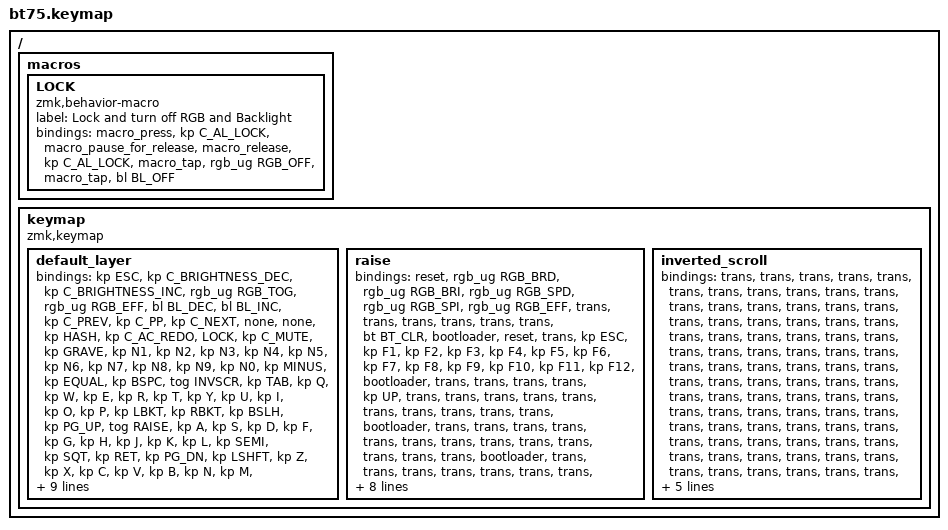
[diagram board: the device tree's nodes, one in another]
#include <behaviors.dtsi>
#include <dt-bindings/zmk/keys.h>
#define HOST_OS 2
#include "../zmk-nodefree-config/helper.h"
#include <dt-bindings/zmk/bt.h>
#include <dt-bindings/zmk/rgb.h>
#include <dt-bindings/zmk/backlight.h>
#include <dt-bindings/zmk/ext_power.h>


/ {
    macros {
        LOCK: LOCK {
            label = "Lock and turn off RGB and Backlight";
            compatible = "zmk,behavior-macro";
            #binding-cells = <0>;
            bindings
			    = <&macro_press &kp C_AL_LOCK>
			    , <&macro_pause_for_release>
			    , <&macro_release &kp C_AL_LOCK>
			    , <&macro_tap &rgb_ug RGB_OFF>
			    , <&macro_tap &bl BL_OFF>
			    ;
        };
    };
};

#define DEFAULT 0
#define RAISE   1
#define INVSCR  2


/ {
	keymap {
		compatible = "zmk,keymap";
		default_layer {
				// ------------------------------------------------------------------------------------------------------------
				// | ESC | F1  | F2  | F3  | F4  | F5  | F6  | F7  | F9  | F9  | F10 | F11 | F12 | PSCRN | INS | DEL	|
				// |  `  |  1  |  2  |  3  |  4  |  5  |  6  |  7  |  8  |  9  |  0  |  -  |  =  |   BKSP   | HOME	|
				// | TAB  |  Q  |  W  |  E  |  R  |  T  |  Y  |  U  |  I  |  O  |  P  |  [  |  ]  |    \    | PG UP |
				// | CAPS  |  A  |  S  |  D  |  F  |  G  |  H  |  J  |  K  |  L  |  ;  |  '  |     ENTER     | PG DN |
				// |  SHIFT    |  Z  |  X  |  C  |  V  |  B  |  N  |  M  |  ,  |  .  | /   |    SHIFT |  UP  |  END  |
				// |  CTL  |  WIN  |  ALT  |            SPACE               | ALT | 1  | CTRL |  LEFT | DOWN | RIGHT |
				// ------------------------------------------------------------------------------------------------------------
			bindings = <
			// 	1 			2 						3 						4 					5 					6 			7 			8 			9 			10 			11 		 		12 	  				13 	   					14 				15 		 			16
				&kp ESC		&kp C_BRIGHTNESS_DEC 	&kp C_BRIGHTNESS_INC 	&rgb_ug RGB_TOG 	&rgb_ug RGB_EFF 	&bl BL_DEC 	&bl BL_INC 	&kp C_PREV 	&kp C_PP 	&kp C_NEXT 	&none 			&none 				&kp HASH 				&kp C_AC_REDO	&LOCK 				&kp C_MUTE
				&kp GRAVE 	&kp N1 					&kp N2 					&kp N3 				&kp N4 				&kp N5 		&kp N6 		&kp N7 		&kp N8 		&kp N9 		&kp N0 			&kp MINUS 			&kp EQUAL 				&kp BSPC 							&tog INVSCR
				&kp TAB		&kp Q 					&kp W 					&kp E 				&kp R 				&kp T 		&kp Y 		&kp U 		&kp I 		&kp O 		&kp P 			&kp LBKT 			&kp RBKT 				&kp BSLH							&kp PG_UP
				&tog RAISE 	&kp A 					&kp S 					&kp D 				&kp F 				&kp G 		&kp H 		&kp J 		&kp K 		&kp L 		&kp SEMI 		&kp SQT 						 			&kp RET								&kp PG_DN
				&kp LSHFT 				 			&kp Z 					&kp X 				&kp C 				&kp V 		&kp B 		&kp N 		&kp M 		&kp COMMA 	&kp DOT 		&kp SLASH			&kp LC(LS(LG(LALT))) 					&kp UP 				&kp C_MENU
				&kp LCTRL 	&kp LALT 				&kp LGUI 														&kp SPACE 													&kp RGUI 		&mo RAISE 			&kp LC(LS(LALT))		&kp LEFT 		&kp DOWN 			&kp RIGHT
			>;
			sensor-bindings = < &inc_dec_kp C_AC_SCROLL_UP C_AC_SCROLL_DOWN &inc_dec_kp C_VOL_UP C_VOL_DN &inc_dec_kp C_VOL_UP C_VOL_DN>;
		};
		raise {
			bindings = <
			// 	1 			2 						3 						4 					5 					6 					7 			8 		9 		10 			11 		 	12 	  			13 	   		14 				15 		 	16
				&reset		&rgb_ug RGB_BRD 		&rgb_ug RGB_BRI 		&rgb_ug RGB_SPD 	&rgb_ug RGB_SPI 	&rgb_ug RGB_EFF 	&trans 		&trans	&trans	&trans		&trans		&trans			&bt BT_CLR	&bootloader		&reset		&trans
				&kp ESC		&kp F1 					&kp F2 					&kp F3 				&kp F4 				&kp F5 				&kp F6 		&kp F7	&kp F8	&kp F9		&kp F10		&kp F11			&kp F12		&bootloader 	&trans		&trans
				&trans		&trans 					&kp UP 					&trans 				&trans 				&trans 				&trans 		&trans	&trans	&trans		&trans		&trans			&trans		&bootloader		&trans
				&trans		&trans 					&trans 					&trans 				&trans 				&trans 				&trans 		&trans	&trans	&trans		&trans		&trans						&bootloader					&trans
				&trans		&trans					&trans 					&trans 				&trans 				&trans 				&trans 		&trans	&trans	&trans		&trans		&trans			&trans 		&bootloader 	&trans 		&trans
				&bt BT_PRV 	&bt BT_NXT				&bt BT_SEL 0           											&trans														&trans		&trans			&trans		&trans			&trans		&trans
			>;
			sensor-bindings = < &inc_dec_kp C_AC_SCROLL_UP C_AC_SCROLL_DOWN &inc_dec_kp C_VOL_UP C_VOL_DN &inc_dec_kp C_AC_SCROLL_UP C_AC_SCROLL_DOWN>;
		};
		inverted_scroll {
			bindings = <
			// 	1 			2 			3 			4 			5 			6 			7 			8 			9 			10 			11 		 	12 	  			13 	   		14 				15 		 	16
				&trans		&trans 		&trans 		&trans 		&trans 		&trans	 	&trans 		&trans		&trans		&trans		&trans		&trans			&trans		&trans			&trans		&trans
				&trans		&trans 		&trans 		&trans 		&trans		&trans 		&trans 		&trans		&trans		&trans		&trans		&trans			&trans		&trans 			&trans		&trans
				&trans		&trans 		&trans		&trans		&trans 		&trans 		&trans 		&trans		&trans		&trans		&trans		&trans			&trans		&trans			&trans
				&trans		&trans 		&trans 		&trans		&trans 		&trans 		&trans 		&trans 		&trans		&trans		&trans		&trans			&trans		&trans						&trans
				&trans		&trans		&trans 		&trans		&trans 		&trans 		&trans 		&trans 		&trans		&trans		&trans		&trans			&trans		&trans 			&trans 		&trans
				&trans 		&trans		&trans              				&trans														&trans		&trans			&trans		&trans			&trans		&trans
			>;
			sensor-bindings = <&inc_dec_kp C_AC_SCROLL_DOWN C_AC_SCROLL_UP &inc_dec_kp C_VOL_DN C_VOL_UP &inc_dec_kp C_AC_SCROLL_DOWN C_AC_SCROLL_UP>;
		};
	};
};
